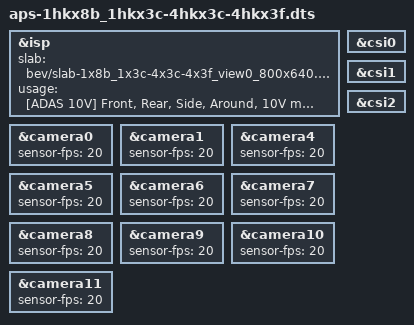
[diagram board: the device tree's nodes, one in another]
/dts-v1/;
/plugin/;

#include "../common/isp-csi-map.dtsi"
#include "base-isp.dtsi"
#include "base-csi-deser-camera.dtsi"
#include "base-desers-3max96724.dtsi"

&isp {
	slab = "bev/slab-1x8b_1x3c-4x3c-4x3f_view0_800x640.bin";
	usage = "[ADAS 10V] Front, Rear, Side, Around, 10V model with hybrid cameras, Around_view0: 800*640";
};
&csi0 {
	status = "okay";
};
&csi1 {
	status = "okay";
};
&csi2 {
	status = "okay";
};

&camera0 {
	#include "../cameras/ox08b_raw14_hk_1920x1080.dtsi"
	sensor-fps = <20>;
	status = "okay";
};
&camera1 {
	#include "../cameras/ox03c_raw14_hk_1920x1080.dtsi"
	sensor-fps = <20>;
	status = "okay";
};
&camera4 {
	#include "../cameras/ox03c_raw14_hk_1920x1080.dtsi"
	sensor-fps = <20>;
	status = "okay";
};
&camera5 {
	#include "../cameras/ox03c_raw14_hk_1920x1080.dtsi"
	sensor-fps = <20>;
	status = "okay";
};
&camera6 {
	#include "../cameras/ox03c_raw14_hk_1920x1080.dtsi"
	sensor-fps = <20>;
	status = "okay";
};
&camera7 {
	#include "../cameras/ox03c_raw14_hk_1920x1080.dtsi"
	sensor-fps = <20>;
	status = "okay";
};
&camera8 {
	#include "../cameras/ox03f_raw12_hk_1920x1536.dtsi"
	sensor-fps = <20>;
	status = "okay";
};
&camera9 {
	#include "../cameras/ox03f_raw12_hk_1920x1536.dtsi"
	sensor-fps = <20>;
	status = "okay";
};
&camera10 {
	#include "../cameras/ox03f_raw12_hk_1920x1536.dtsi"
	sensor-fps = <20>;
	status = "okay";
};
&camera11 {
	#include "../cameras/ox03f_raw12_hk_1920x1536.dtsi"
	sensor-fps = <20>;
	status = "okay";
};
